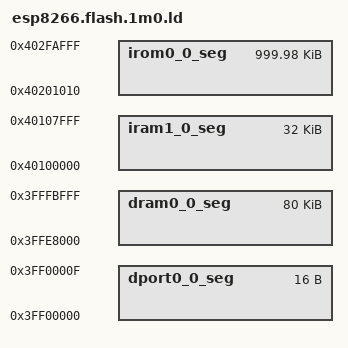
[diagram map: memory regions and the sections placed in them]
/* Flash Split for 1M chips */
/* sketch 999KB */
/* eeprom 20KB */

MEMORY
{
  dport0_0_seg :                        org = 0x3FF00000, len = 0x10
  dram0_0_seg :                         org = 0x3FFE8000, len = 0x14000
  iram1_0_seg :                         org = 0x40100000, len = 0x8000
  irom0_0_seg :                         org = 0x40201010, len = 0xf9ff0
}

PROVIDE ( _SPIFFS_start = 0x402FB000 );
PROVIDE ( _SPIFFS_end = 0x402FB000 );
PROVIDE ( _SPIFFS_page = 0 );
PROVIDE ( _SPIFFS_block = 0 );

INCLUDE "esp8266.flash.common.ld"
